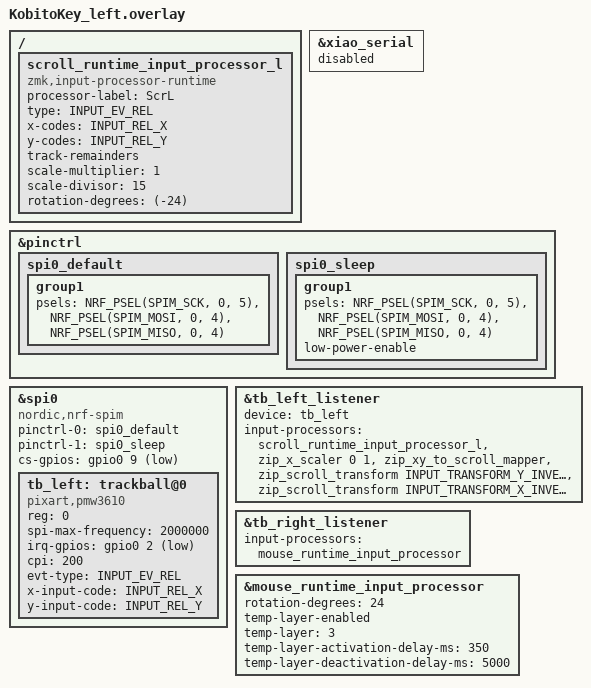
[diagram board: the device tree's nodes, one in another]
#include "kobitokey.dtsi"
#include <zephyr/dt-bindings/input/input-event-codes.h>
#include <dt-bindings/zmk/keys.h>
#include <input/processors.dtsi>
#include <input/processors/sensor_rotation.dtsi>
#include <input/processors/runtime-input-processor.dtsi>

/* XIAOのUARTを無効化（USBをStudio通信に使うため） */
&xiao_serial { status = "disabled"; };

/* ===== SPI（センサーとの通信路）のピン設定：変更なし ===== */
&pinctrl {
    spi0_default: spi0_default {
        group1 {
            psels = <NRF_PSEL(SPIM_SCK,  0, 5)>,
                    <NRF_PSEL(SPIM_MOSI, 0, 4)>,
                    <NRF_PSEL(SPIM_MISO, 0, 4)>;
        };
    };
    spi0_sleep: spi0_sleep {
        group1 {
            psels = <NRF_PSEL(SPIM_SCK,  0, 5)>,
                    <NRF_PSEL(SPIM_MOSI, 0, 4)>,
                    <NRF_PSEL(SPIM_MISO, 0, 4)>;
            low-power-enable;
        };
    };
};

/* ===== 左のトラックボール本体：変更なし ===== */
&spi0 {
    status = "okay";
    compatible = "nordic,nrf-spim";
    pinctrl-0 = <&spi0_default>;
    pinctrl-1 = <&spi0_sleep>;
    pinctrl-names = "default", "sleep";
    cs-gpios = <&gpio0 9 GPIO_ACTIVE_LOW>;

    tb_left: trackball@0 {
        status = "okay";
        compatible = "pixart,pmw3610";
        reg = <0>;
        spi-max-frequency = <2000000>;
        irq-gpios = <&gpio0 2 (GPIO_ACTIVE_LOW | GPIO_PULL_UP)>;
        cpi = <200>;                    /* センサー感度（PMW3610の最小値） */

        evt-type = <INPUT_EV_REL>;
        x-input-code = <INPUT_REL_X>;
        y-input-code = <INPUT_REL_Y>;
    };
};

/* ============================================================
 * DYA Studio 対応：実行中に値を書き換えられる processor
 *
 * 【重要】runtime processor は x-codes/y-codes で指定した
 * イベントコードに一致したときだけ動作する。
 * zip_xy_to_scroll_mapper を通すと REL_X/REL_Y は
 * REL_HWHEEL/REL_WHEEL に変わるので、mapper より
 * 【先】に置かないと scale-divisor が無視される。
 * ============================================================ */
/ {
    /* 左ボール用（processor-label が DYA Studio 上での表示名） */
    scroll_runtime_input_processor_l: scroll_runtime_input_processor_l {
        compatible = "zmk,input-processor-runtime";
        processor-label = "ScrL";
        type = <INPUT_EV_REL>;
        x-codes = <INPUT_REL_X>;
        y-codes = <INPUT_REL_Y>;
        track-remainders;               /* 端数を持ち越して滑らかにする */
        scale-multiplier = <1>;
        scale-divisor = <15>;           /* ★感度。大きくするほど遅くなる */
        rotation-degrees = <(-24)>;     /* 取り付け角度の補正 */
        #input-processor-cells = <0>;
    };
};

/* ===== 左ボール = スクロール専用 ===== */
&tb_left_listener {
    status = "okay";
    device = <&tb_left>;

    input-processors =
            <&scroll_runtime_input_processor_l>,               /* ★X/Yの段階で回転と減速 */
            <&zip_x_scaler 0 1>,                               /* 横スクロールを殺す */
            <&zip_xy_to_scroll_mapper>,                        /* X/Y移動 → スクロール */
            <&zip_scroll_transform INPUT_TRANSFORM_Y_INVERT>,  /* Y反転 */
            <&zip_scroll_transform INPUT_TRANSFORM_X_INVERT>;  /* X反転 */
};

/* ===== 右ボール = マウスカーソル＋オートマウスレイヤー ===== */
/* device は kobitokey.dtsi で &tb_right_split に設定済み */
&tb_right_listener {
    status = "okay";

    input-processors = <&mouse_runtime_input_processor>;
};

/* ===== 起動時の初期値（後から DYA Studio で自由に変更できます）===== */
&mouse_runtime_input_processor {
    rotation-degrees = <24>;                   /* 取り付け角度の補正 */

    /* オートマウスレイヤー：ボールを動かすと自動でレイヤー3(MOUSE)へ */
    temp-layer-enabled;
    temp-layer = <3>;
    temp-layer-activation-delay-ms = <350>;    /* キー入力直後は発動しない（誤爆防止） */
    temp-layer-deactivation-delay-ms = <5000>; /* 5秒操作しなければ戻る */
};
